# A34L71x register map
Vendor: ABOV Semiconductor Co., Ltd.; File version: 1.0
ARM Cortex-M4 32-bit MCU+FPU, CPU clock up to 32MHz, etc.
CPU: CM4 r0p1, little endian, MPU, FPU, VTOR, 4 interrupt priority bits
Registers are 32-bit, read-write, reset 0x0 unless marked. A register's access mark holds for its fields unless they carry their own. Offsets are from the block's base; lines under a group give offsets from that group; [hi:lo] are bit positions; {n}, {i} and the like mark numbered series; 'fields as' and 'values as' point back to an identical list; <NAME> marks a mode.

## Memory map
0x40000000 SCU size 0x100 — System Control Unit
0x40000200 WDT size 0x100 — WATCH-DOG TIMER
0x40000400 DMA0 size 0x10
0x40000410 DMA1 size 0x10
0x40000420 DMA2 size 0x10
0x40000430 DMA3 size 0x10
0x40000440 DMA4 size 0x10
0x40000450 DMA5 size 0x10
0x40000460 DMA6 size 0x10
0x40000600 FRT size 0x100 — Free Run Timer
0x40000900 RTC size 0x100 — Real-time clock
{0x40003000+0x40*n} TIMER{n} size 0x40 (n=0..7)
0x40004000 HSICMU size 0x20 — HIGH-SPEED INTERNAL OSC CLOCK MANAGEMENT UNIT
0x40005000 LCD size 0x100 — LCD Driver
0x40008000 UART size 0x100 — Universal Asynchronous Receiver/Transmitter
0x40008800 USART10 size 0x100
0x40008900 USART11 size 0x100
0x40008C00 LPUART0 size 0x100
0x40008D00 LPUART1 size 0x100
0x40009000 SPI0 size 0x100
0x40009100 SPI1 size 0x100
0x4000A000 I2C0 size 0x100
0x4000A100 I2C1 size 0x100
0x4000B000 VREFBUF size 0x10 — Voltage Reference buffer
0x4000B300 OPAMP size 0xC — Operational Amplifier
0x4000B800 DAC0 size 0x8
0x4000B900 DAC1 size 0x8
0x4000F000 CHIPCONFIG size 0x10 — Chip Configuration Data
0x41000000 CFMC size 0x1000 — CODE FLASH MEMORY CONTROLLER
0x41001000 DFMC size 0x1000 — DATA FLASH MEMORY CONTROLLER
0x41002000 CRC size 0x1000 — Cyclic Redundancy Check calculation module
0x41004000 PA size 0x100
0x41004100 PB size 0x100
0x41004200 PC size 0x100
0x41004300 PD size 0x100
0x41004400 PE size 0x100
0x41004500 PF size 0x100
0x41004FF0 PORTEN size 0xF — General Port Access Enable
0x41005000 ADC0 size 0x100
0x41005100 ADC1 size 0x100
0x41006000 USB size 0x230 — Universal Serial Bus 1.1
0x50000400 DMA size 0x10 — Direct Memory Access Control 0
0x50003000 TIMER size 0x40 — TIMER COUNTER 0
0x50008800 USART size 0x100 — USART 10 (UART + SPI)
0x50008C00 LPUARTn size 0x100 — Low Power UART 0
0x50009000 SPI size 0x100 — Serial Peripheral Interface Bus
0x5000A000 I2C size 0x100 — Inter-Integrated Circuit
0x5000B800 DAC size 0x8 — 12-BIT Digital-to-analog (D/A) converter
0x51004000 PCU size 0x100 — General Port
0x51005000 ADC size 0x100 — 12-BIT A/D CONVERTER

## Interrupts
0 LVI (SCU)
1 SYSCLKFAIL (SCU)
2 HSEFAIL (SCU)
3 LSEFAIL (SCU)
6 WDT
8 FRT
11 CFMC
12 DFMC
{n+15} TIMER{n} (n=0..7)
29 RTC
30 VREFBUF
36 GPIOA (PA)
37 GPIOB (PB)
38 GPIOC (PC)
39 GPIOD (PD)
40 GPIOE (PE)
41 GPIOF (PF)
44 USB
50 LPUART0
51 LPUART1
55 SPI0
56 SPI1
60 I2C0
61 I2C1
63 UART
69 USART10
70 USART11
74 ADC0
75 ADC1
85 CRC

## CHIPCONFIG — Chip Configuration Data
Base 0x4000F000
0x00 VENDID ro reset 0x41424F56 — Vendor identification bits
0x04 CHIPID ro reset 0x4C347160 — Chip ID bits
0x08 REVNO 8-bit ro — Chip revision number

## PCU — General Port
Base 0x51004000
Same registers: PA 0x41004000, PB 0x41004100, PC 0x41004200, PD 0x41004300, PE 0x41004400, PF 0x41004500
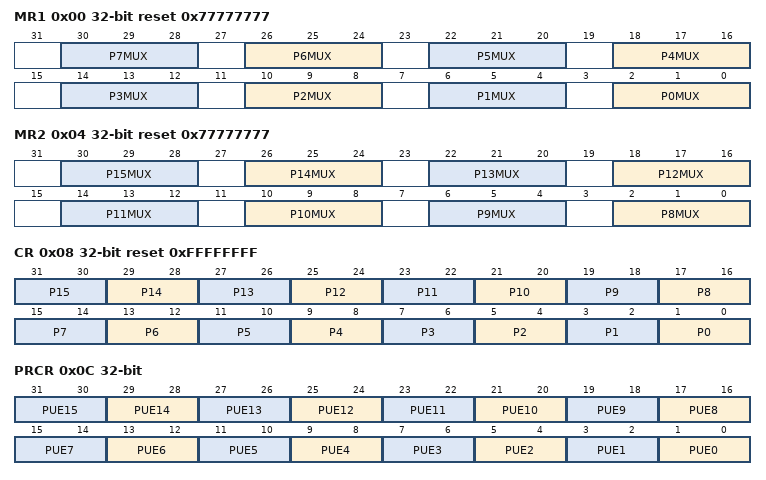
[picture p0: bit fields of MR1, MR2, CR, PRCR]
0x00 MR1 reset 0x77777777 — Port n MUX1 Selection Register
  [4n+2:4n] P{n}MUX (n=0..7) — Pin {n} Mode Selection bits
0x04 MR2 reset 0x77777777 — Port n MUX2 Selection Register
  [4n-30:4n-32] P{n}MUX (n=8..15) — Pin {n} Mode Selection bits
0x08 CR reset 0xFFFFFFFF — Port n Type Selection Register
  [2n+1:2n] P{n} (n=0..15) — Pin {n} Type Selection bit
0x0C PRCR — Port n Pull-up/down Selection Register
  [2n+1:2n] PUE{n} (n=0..15) — Pin {n} Pull-up/down Selection bits
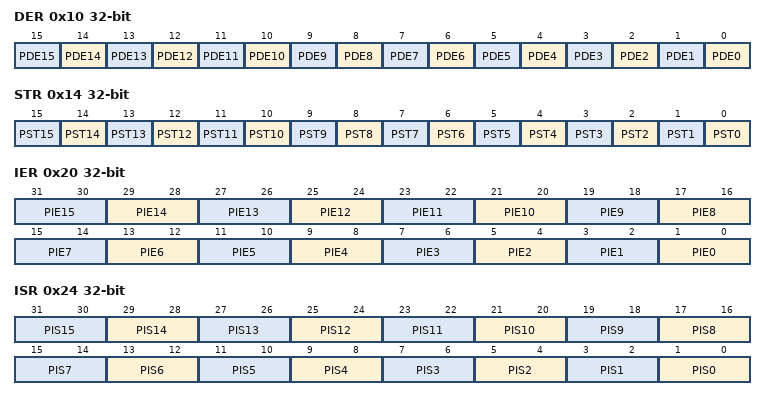
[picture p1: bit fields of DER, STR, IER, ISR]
0x10 DER — Port n Debounce Enable Register
  [n] PDE{n} (n=0..15) — Pin {n} Debounce Enable bits
0x14 STR — Port n Strength Selection Register
  [n] PST{n} (n=0..15) — Pin {n} Strength Selection bit
0x20 IER — Port n Interrupt Enable Register
  [2n+1:2n] PIE{n} (n=0..15) — Pin {n} Interrupt Enable bit
0x24 ISR — Port n Interrupt Status Register
  [2n+1:2n] PIS{n} (n=0..15) — Pin {n} Interrupt Status bit
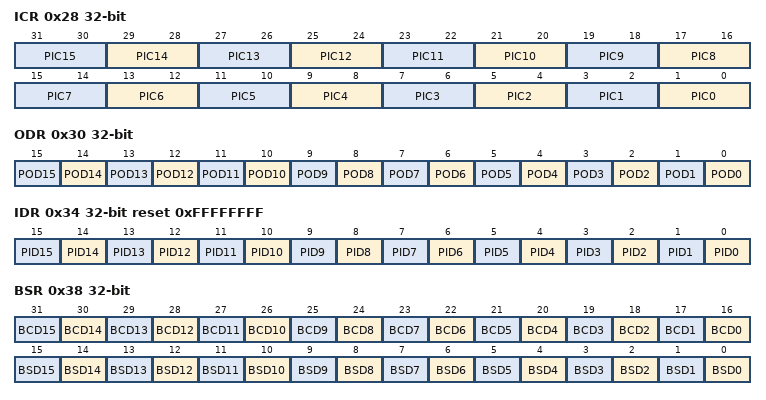
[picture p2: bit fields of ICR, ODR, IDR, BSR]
0x28 ICR — Port n Interrupt Control Register
  [2n+1:2n] PIC{n} (n=0..15) — Pin {n} Interrupt Control bit
0x30 ODR — Port n Output Data Register
  [n] POD{n} (n=0..15) — Pin {n} Output data bit
0x34 IDR ro reset 0xFFFFFFFF — Port n Input Data Register
  [n] PID{n} rw (n=0..15) — Pin {n} Input data bit
0x38 BSR wo — Port n Bit Set/Clear Register
  [n+16] BCD{n} (n=0..15) — Port {n} Bit Clear bits
  [n] BSD{n} (n=0..15) — Port {n} Bit Set bits
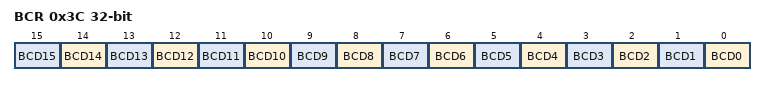
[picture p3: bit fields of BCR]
0x3C BCR wo — Port n Bit Reset Register
  [n] BCD{n} (n=0..15) — Port {n} Bit Clear bits
